# MCXN236 register map
Vendor: nxp.com; File version: 1.0
CPU: CM33 r2p0, little endian, MPU, FPU, VTOR, 3 interrupt priority bits
Registers are 32-bit, read-write, reset 0x0 unless marked. A register's access mark holds for its fields unless they carry their own. Offsets are from the block's base; [hi:lo] are bit positions; lines under a group give offsets from that group; {n}, {i} and the like mark numbered series.

## MRT0 — Multi-Rate Timer (MRT)
Base 0x40013000
{0x0+0x10*i} CHANNEL[{i}] (i=0..3) group
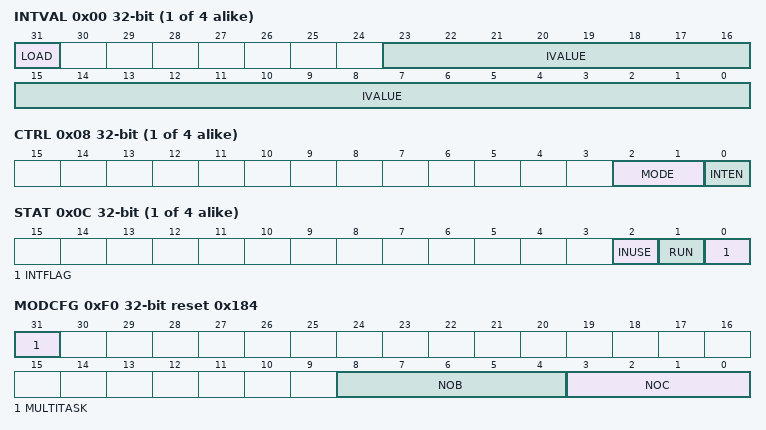
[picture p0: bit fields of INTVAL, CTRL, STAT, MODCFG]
  0x00 INTVAL — Time Interval Value
    [31] LOAD — Force Load Enable
      0=NO_FORCE_LOAD; 1=FORCE_LOAD
    [23:0] IVALUE — Time Interval Load Value.
  0x04 TIMER ro reset 0xFFFFFF
    [23:0] VALUE — Current Timer Value
  0x08 CTRL — Control
    [2:1] MODE — MRT Operating mode
      0=REPEAT_INTERRUPT_MODE; 1=ONE_SHOT_INTERRUPT_MODE; 2=ONE_SHOT_STALL_MODE
    [0] INTEN — Interrupt request
      0=DISABLED; 1=ENABLED
  0x0C STAT — Status
    [2] INUSE write-1-clears — Channel-In-Use flag
      0=NO (This timer channel is not in use.); 1=YES (This timer channel is in use.)
    [1] RUN ro — Timer n State
      0=IDLE_STATE; 1=RUNNING
    [0] INTFLAG — Monitors the interrupt flag. Writing 0 indicates no pending interrupt or no operation. Writing 1 indicates pending interrupt, because TIMERn has reached the end of the time interval. If the INTEN bit in the CONTROL n is also set to 1, then the interrupt for timer channel n and the global interrupt are generated. Writing a 1 to INTFLAG bit clears the interrupt request.
      0=NO_PENDING_INTERRUPT; 1=PENDING_INTERRUPT
0xF0 MODCFG reset 0x184 — Module Configuration
  [31] MULTITASK
    0=HARDWARE_STATUS_MODE; 1=MULTI_TASK_MODE
  [8:4] NOB — Number of Bits
  [3:0] NOC — Number of Channels
0xF4 IDLE_CH ro — Idle Channel
  [7:4] CHAN
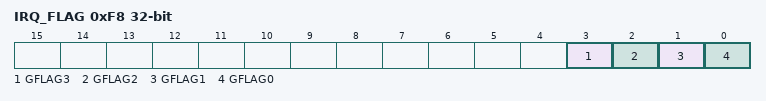
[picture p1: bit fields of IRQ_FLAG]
0xF8 IRQ_FLAG — Global Interrupt Flag
  [3] GFLAG3 — Interrupt Flag
  [2] GFLAG2 — Interrupt Flag
  [1] GFLAG1 — Interrupt Flag
  [0] GFLAG0 — Interrupt Flag
    0=NO_PENDING_INTERRUPT; 1=PENDING_INTERRUPT

## WWDT0 — WWDT
Base 0x40016000
Same registers: WWDT1 0x40017000
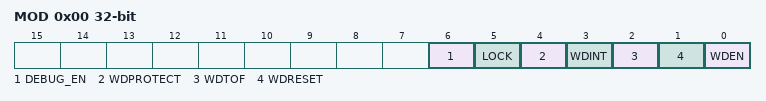
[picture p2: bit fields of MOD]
0x00 MOD — Mode
  [6] DEBUG_EN — Debug Enable
    0=DISABLE (Disabled); 1=ENABLE (Enabled)
  [5] LOCK
    0=NO_LOCK; 1=LOCK
  [4] WDPROTECT — Watchdog Update Mode
    0=FLEXIBLE; 1=THRESHOLD
  [3] WDINT write-1-clears — Warning Interrupt Flag
    0=NO_FLAG; 1=FLAG
  [2] WDTOF — Watchdog Timeout Flag
    0=CLEAR (Watchdog event has not occurred.); 1=RESET (Watchdog event has occurred (causes a chip reset if WDRESET = 1).)
  [1] WDRESET — Watchdog Reset Enable
    0=INTERRUPT; 1=RESET
  [0] WDEN — Watchdog Enable
    0=STOP (Timer stopped); 1=RUN (Timer running)
0x04 TC reset 0xFF — Timer Constant
  [23:0] COUNT — Watchdog Timeout Value
0x08 FEED wo reset not defined — Feed Sequence
  [7:0] FEED — Feed Value
0x0C TV ro reset 0xFF — Timer Value
  [23:0] COUNT — Counter Timer Value
0x14 WARNINT — Warning Interrupt Compare Value
  [9:0] WARNINT — Watchdog Warning Interrupt Compare Value
0x18 WINDOW reset 0xFFFFFF — Window Compare Value
  [23:0] WINDOW — Watchdog Window Value

## GDET0
Base 0x40024000
Same registers: GDET1__APB 0x40025000
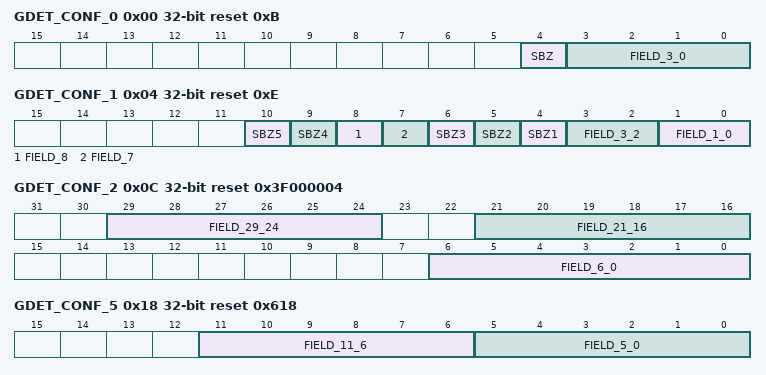
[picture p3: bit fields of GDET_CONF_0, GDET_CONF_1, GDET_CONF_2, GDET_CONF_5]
0x00 GDET_CONF_0 reset 0xB — GDET Configuration 0 Register
  [4] SBZ — Should Be Left to Zero
  [3:0] FIELD_3_0 — GDET Configuration 0 Field 3_0
0x04 GDET_CONF_1 reset 0xE — GDET Configuration 1 Register
  [10] SBZ5 — Should Be Left to Zero
  [9] SBZ4 — Should Be Left to Zero
  [8] FIELD_8 — GDET Configuration 1 Field 8
  [7] FIELD_7 — GDET Configuration 1 Field 7
  [6] SBZ3 — Should Be Left to Zero
  [5] SBZ2 — Should Be Left to Zero
  [4] SBZ1 — Should Be Left to Zero
  [3:2] FIELD_3_2 — GDET Configuration 1 Field 3_2
  [1:0] FIELD_1_0 — GDET Configuration 1 Field 1_0
0x08 GDET_ENABLE1 — GDET Enable Register
  [0] EN1 — If set, the detector will be clock gated
0x0C GDET_CONF_2 reset 0x3F000004 — GDET Configuration 2 Register
  [29:24] FIELD_29_24 — GDET Configuration 2 Field 29_24
  [21:16] FIELD_21_16 — GDET Configuration 2 Field 21_16
  [6:0] FIELD_6_0 — GDET Configuration 2 Field 6_0
0x10 GDET_CONF_3 reset 0x4 — GDET Configuration 3 Register
  [6:0] FIELD_6_0 — GDET Configuration 3 Field 6_0
0x14 GDET_CONF_4 reset 0x4 — GDET Configuration 4 Register
  [6:0] FIELD_6_0 — GDET Configuration 4 Field 6_0
0x18 GDET_CONF_5 reset 0x618 — GDET Configuration 5 Register
  [11:6] FIELD_11_6 — GDET Configuration 5 Field 11_6
  [5:0] FIELD_5_0 — GDET Configuration 5 Field 5_0
0xFC0 GDET_RESET
  [3] SFT_RST — Soft Reset for the Core Reset
0xFC4 GDET_TEST
  [0] SBZ — Should Be Left to Zero
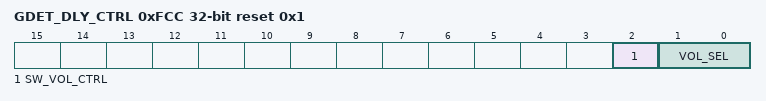
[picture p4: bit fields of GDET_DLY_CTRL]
0xFCC GDET_DLY_CTRL reset 0x1 — GDET Delay Control Register
  [2] SW_VOL_CTRL — Select the Control of the Trim Code to the Delay Line
  [1:0] VOL_SEL — GDET Delay Control of the Voltage Mode
